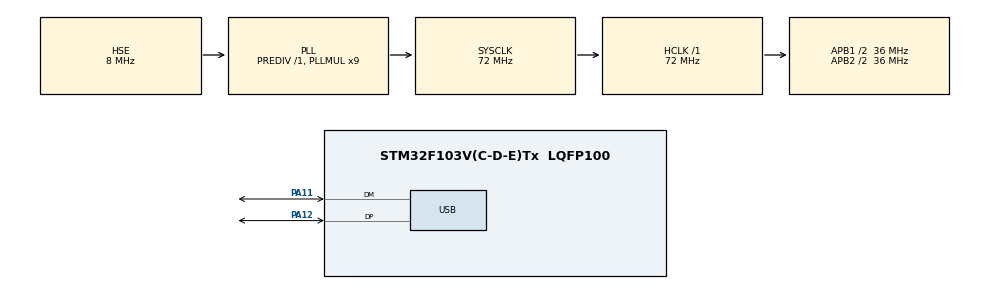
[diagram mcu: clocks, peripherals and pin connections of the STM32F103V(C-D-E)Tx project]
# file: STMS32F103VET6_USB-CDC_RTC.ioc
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Mcu.Family=STM32F1
Mcu.Name=STM32F103V(C-D-E)Tx
Mcu.Package=LQFP100
NVIC.PriorityGroup=NVIC_PRIORITYGROUP_4
NVIC.USB_LP_CAN1_RX0_IRQn=true\:0\:0\:false\:false\:true
OSC_IN.Mode=HSE-External-Oscillator
OSC_IN.Signal=RCC_OSC_IN
OSC_OUT.Mode=HSE-External-Oscillator
OSC_OUT.Signal=RCC_OSC_OUT
PA11.Mode=Device
PA11.Signal=USB_DM
PA12.Mode=Device
PA12.Signal=USB_DP
PA13.Mode=Serial_Wire
PA13.Signal=SYS_JTMS-SWDIO
PA14.Mode=Serial_Wire
PA14.Signal=SYS_JTCK-SWCLK
PC14-OSC32_IN.Mode=LSE-External-Oscillator
PC14-OSC32_IN.Signal=RCC_OSC32_IN
PC15-OSC32_OUT.Mode=LSE-External-Oscillator
PC15-OSC32_OUT.Signal=RCC_OSC32_OUT
ProjectManager.HeapSize=0x200
ProjectManager.StackSize=0x400
ProjectManager.TargetToolchain=MDK-ARM V5
RCC.AHBFreq_Value=72000000
RCC.APB1CLKDivider=RCC_HCLK_DIV2
RCC.APB1Freq_Value=36000000
RCC.APB1TimFreq_Value=72000000
RCC.APB2CLKDivider=RCC_HCLK_DIV2
RCC.APB2Freq_Value=36000000
RCC.APB2TimFreq_Value=72000000
RCC.FLatency=FLASH_LATENCY_2
RCC.HCLKFreq_Value=72000000
RCC.HSIState=RCC_HSI_ON
RCC.PLLMUL=RCC_PLL_MUL9
RCC.SYSCLKFreq_VALUE=72000000
RCC.SYSCLKSource=RCC_SYSCLKSOURCE_PLLCLK
RCC.USBFreq_Value=48000000
RCC.USBPrescaler=RCC_USBCLKSOURCE_PLL_DIV1_5
RTC.Date=26
RTC.Format=RTC_FORMAT_BIN
RTC.Hours=7
RTC.Minutes=5
RTC.Month=RTC_MONTH_NOVEMBER
RTC.OutPut=RTC_OUTPUTSOURCE_SECOND
RTC.Year=16
USB.ep0_mps=DEP0CTL_MPS_64
USB_DEVICE.CLASS_NAME_FS=CDC
USB_DEVICE.MANUFACTURER_STRING=electronic4U
USB_DEVICE.PID_CDC_FS=2510
USB_DEVICE.USBD_HandleTypeDef=hUsbDeviceFS
USB_DEVICE.USBD_SUPPORT_USER_STRING=1
USB_DEVICE.VID=1706
USB_DEVICE.VirtualMode=Cdc
USB_DEVICE.VirtualModeFS=Cdc_FS
VP_RTC_VS_RTC_Activate.Mode=RTC_Enabled
VP_RTC_VS_RTC_Calendar.Mode=RTC_Calendar
VP_USB_DEVICE_VS_USB_DEVICE_CDC_FS.Mode=CDC_FS
board=STMS32F103VET6_USB-CDC_RTC

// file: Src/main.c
/**
  ******************************************************************************
  * File Name          : main.c
  * Description        : Main program body
  ******************************************************************************
  *
  * Copyright (c) 2016 STMicroelectronics International N.V.
  * All rights reserved.
  *
  * Redistribution and use in source and binary forms, with or without
  * modification, are permitted, provided that the following conditions are met:
  *
  * 1. Redistribution of source code must retain the above copyright notice,
  *    this list of conditions and the following disclaimer.
  * 2. Redistributions in binary form must reproduce the above copyright notice,
  *    this list of conditions and the following disclaimer in the documentation
  *    and/or other materials provided with the distribution.
  * 3. Neither the name of STMicroelectronics nor the names of other
  *    contributors to this software may be used to endorse or promote products
  *    derived from this software without specific written permission.
  * 4. This software, including modifications and/or derivative works of this
  *    software, must execute solely and exclusively on microcontroller or
  *    microprocessor devices manufactured by or for STMicroelectronics.
  * 5. Redistribution and use of this software other than as permitted under
  *    this license is void and will automatically terminate your rights under
  *    this license.
  *
  * THIS SOFTWARE IS PROVIDED BY STMICROELECTRONICS AND CONTRIBUTORS "AS IS"
  * AND ANY EXPRESS, IMPLIED OR STATUTORY WARRANTIES, INCLUDING, BUT NOT
  * LIMITED TO, THE IMPLIED WARRANTIES OF MERCHANTABILITY, FITNESS FOR A
  * PARTICULAR PURPOSE AND NON-INFRINGEMENT OF THIRD PARTY INTELLECTUAL PROPERTY
  * RIGHTS ARE DISCLAIMED TO THE FULLEST EXTENT PERMITTED BY LAW. IN NO EVENT
  * SHALL STMICROELECTRONICS OR CONTRIBUTORS BE LIABLE FOR ANY DIRECT, INDIRECT,
  * INCIDENTAL, SPECIAL, EXEMPLARY, OR CONSEQUENTIAL DAMAGES (INCLUDING, BUT NOT
  * LIMITED TO, PROCUREMENT OF SUBSTITUTE GOODS OR SERVICES; LOSS OF USE, DATA,
  * OR PROFITS; OR BUSINESS INTERRUPTION) HOWEVER CAUSED AND ON ANY THEORY OF
  * LIABILITY, WHETHER IN CONTRACT, STRICT LIABILITY, OR TORT (INCLUDING
  * NEGLIGENCE OR OTHERWISE) ARISING IN ANY WAY OUT OF THE USE OF THIS SOFTWARE,
  * EVEN IF ADVISED OF THE POSSIBILITY OF SUCH DAMAGE.
  *
  ******************************************************************************
  */
#include "main.h"
#include "stm32f1xx_hal.h"
#include "usb_device.h"

/* USER CODE BEGIN Includes */
#include "usbd_cdc_if.h"
#include "stdio.h"
#include "string.h"
/* USER CODE END Includes */

RTC_HandleTypeDef hrtc;

/* USER CODE BEGIN PV */
/* Private variables ---------------------------------------------------------*/

/* USER CODE END PV */

void SystemClock_Config(void);
void Error_Handler(void);
static void MX_GPIO_Init(void);
static void MX_RTC_Init(void);

/* USER CODE BEGIN PFP */
/* Private function prototypes -----------------------------------------------*/

/* USER CODE END PFP */

/* USER CODE BEGIN 0 */
uint8_t Second, Minute, Hour, Date, Day, Month, Year;
RTC_TimeTypeDef sTime;
RTC_DateTypeDef DateToUpdate;

uint8_t RX_Data[64];
uint8_t RX_Size;
uint8_t mystring[]="Electronic4U \r";
void Sent_Via_USB(uint8_t Data);

void Sent_Via_USB(uint8_t Data)
{
	uint8_t Sen_Data[1];
	sprintf((char *)Sen_Data,"%d",Data);
	CDC_Transmit_FS(Sen_Data, strlen((const char*)Sen_Data));
}
/* USER CODE END 0 */

int main(void)
{

  /* MCU Configuration----------------------------------------------------------*/

  /* Reset of all peripherals, Initializes the Flash interface and the Systick. */
  HAL_Init();

  /* Configure the system clock */
  SystemClock_Config();

  /* Initialize all configured peripherals */
  MX_GPIO_Init();
  MX_RTC_Init();
  MX_USB_DEVICE_Init();

  /* Infinite loop */
  while (1)
  {

  /* USER CODE BEGIN 3 */
		//CDC_Transmit_FS(mystring, strlen((const char*)mystring));
		//HAL_GPIO_TogglePin(GPIOC, GPIO_PIN_13);
		//HAL_Delay(500);
		HAL_RTC_GetTime(&hrtc,&sTime,RTC_FORMAT_BIN);
		HAL_RTC_GetDate(&hrtc,&DateToUpdate,RTC_FORMAT_BIN);
		Second=sTime.Seconds;
		Minute=sTime.Minutes;
		Hour=sTime.Hours;
		Day=DateToUpdate.Date;
		Date=DateToUpdate.WeekDay;
		Month=DateToUpdate.Month;
		Year=DateToUpdate.Year;

		Sent_Via_USB(Second);

		HAL_Delay(1000);

  }
  /* USER CODE END 3 */

}

/** System Clock Configuration
*/
void SystemClock_Config(void)
{

  RCC_OscInitTypeDef RCC_OscInitStruct;
  RCC_ClkInitTypeDef RCC_ClkInitStruct;
  RCC_PeriphCLKInitTypeDef PeriphClkInit;

    /**Initializes the CPU, AHB and APB busses clocks
    */
  RCC_OscInitStruct.OscillatorType = RCC_OSCILLATORTYPE_LSI|RCC_OSCILLATORTYPE_HSE;
  RCC_OscInitStruct.HSEState = RCC_HSE_ON;
  RCC_OscInitStruct.HSEPredivValue = RCC_HSE_PREDIV_DIV1;
  RCC_OscInitStruct.HSIState = RCC_HSI_ON;
  RCC_OscInitStruct.LSIState = RCC_LSI_ON;
  RCC_OscInitStruct.PLL.PLLState = RCC_PLL_ON;
  RCC_OscInitStruct.PLL.PLLSource = RCC_PLLSOURCE_HSE;
  RCC_OscInitStruct.PLL.PLLMUL = RCC_PLL_MUL9;
  if (HAL_RCC_OscConfig(&RCC_OscInitStruct) != HAL_OK)
  {
    Error_Handler();
  }

    /**Initializes the CPU, AHB and APB busses clocks
    */
  RCC_ClkInitStruct.ClockType = RCC_CLOCKTYPE_HCLK|RCC_CLOCKTYPE_SYSCLK
                              |RCC_CLOCKTYPE_PCLK1|RCC_CLOCKTYPE_PCLK2;
  RCC_ClkInitStruct.SYSCLKSource = RCC_SYSCLKSOURCE_PLLCLK;
  RCC_ClkInitStruct.AHBCLKDivider = RCC_SYSCLK_DIV1;
  RCC_ClkInitStruct.APB1CLKDivider = RCC_HCLK_DIV2;
  RCC_ClkInitStruct.APB2CLKDivider = RCC_HCLK_DIV2;

  if (HAL_RCC_ClockConfig(&RCC_ClkInitStruct, FLASH_LATENCY_2) != HAL_OK)
  {
    Error_Handler();
  }

  PeriphClkInit.PeriphClockSelection = RCC_PERIPHCLK_RTC|RCC_PERIPHCLK_USB;
  PeriphClkInit.RTCClockSelection = RCC_RTCCLKSOURCE_LSI;
  PeriphClkInit.UsbClockSelection = RCC_USBCLKSOURCE_PLL_DIV1_5;
  if (HAL_RCCEx_PeriphCLKConfig(&PeriphClkInit) != HAL_OK)
  {
    Error_Handler();
  }

    /**Configure the Systick interrupt time
    */
  HAL_SYSTICK_Config(HAL_RCC_GetHCLKFreq()/1000);

    /**Configure the Systick
    */
  HAL_SYSTICK_CLKSourceConfig(SYSTICK_CLKSOURCE_HCLK);

  /* SysTick_IRQn interrupt configuration */
  HAL_NVIC_SetPriority(SysTick_IRQn, 0, 0);
}

/* RTC init function */
static void MX_RTC_Init(void)
{

  RTC_TimeTypeDef sTime;
  RTC_DateTypeDef DateToUpdate;

    /**Initialize RTC Only
    */
  hrtc.Instance = RTC;
  hrtc.Init.AsynchPrediv = RTC_AUTO_1_SECOND;
  hrtc.Init.OutPut = RTC_OUTPUTSOURCE_SECOND;
  if (HAL_RTC_Init(&hrtc) != HAL_OK)
  {
    Error_Handler();
  }

    /**Initialize RTC and set the Time and Date
    */
  sTime.Hours = 7;
  sTime.Minutes = 5;
  sTime.Seconds = 0;

  if (HAL_RTC_SetTime(&hrtc, &sTime, RTC_FORMAT_BIN) != HAL_OK)
  {
    Error_Handler();
  }

  DateToUpdate.WeekDay = RTC_WEEKDAY_MONDAY;
  DateToUpdate.Month = RTC_MONTH_NOVEMBER;
  DateToUpdate.Date = 26;
  DateToUpdate.Year = 16;

  if (HAL_RTC_SetDate(&hrtc, &DateToUpdate, RTC_FORMAT_BIN) != HAL_OK)
  {
    Error_Handler();
  }

}

/** Configure pins as
        * Analog
        * Input
        * Output
        * EVENT_OUT
        * EXTI
*/
static void MX_GPIO_Init(void)
{

  /* GPIO Ports Clock Enable */
  __HAL_RCC_GPIOC_CLK_ENABLE();
  __HAL_RCC_GPIOA_CLK_ENABLE();

}

void Error_Handler(void)
{
  while(1)
  {
  }
}

/************************ (C) COPYRIGHT STMicroelectronics *****END OF FILE****/
